VERSION ""

NS_ :

BS_:

BU_:

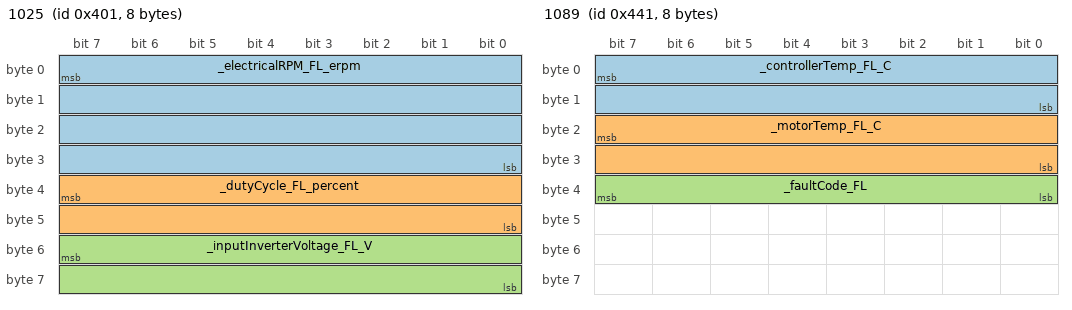
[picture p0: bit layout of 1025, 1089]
BO_ 1025 1025: 8 Vector__XXX
 SG_ _electricalRPM_FL_erpm : 7|32@0+ (1,0) [0|0] "angular_speed:rpm" Vector__XXX
 SG_ _dutyCycle_FL_percent : 39|16@0- (0.1,0) [0|0] "fraction:%" Vector__XXX
 SG_ _inputInverterVoltage_FL_V : 55|16@0- (1,0) [0|0] "voltage:V" Vector__XXX

BO_ 1057 1057: 8 Vector__XXX
 SG_ _motorCurrent_FL_Apk : 7|16@0- (0.1,0) [0|0] "current:A" Vector__XXX
 SG_ _batteryCurrent_FL_A : 23|16@0- (0.1,0) [0|0] "current:A" Vector__XXX

BO_ 1089 1089: 8 Vector__XXX
 SG_ _controllerTemp_FL_C : 7|16@0- (0.1,0) [0|0] "temperature:C" Vector__XXX
 SG_ _motorTemp_FL_C : 23|16@0- (0.1,0) [0|0] "temperature:C" Vector__XXX
 SG_ _faultCode_FL : 39|8@0+ (1,0) [0|0] "unitless:" Vector__XXX

BO_ 1121 1121: 8 Vector__XXX
 SG_ _idPeak_FL_A : 7|32@0- (0.01,0) [0|0] "current:A" Vector__XXX
 SG_ _iqPeak_FL_A : 39|32@0- (0.01,0) [0|0] "current:A" Vector__XXX

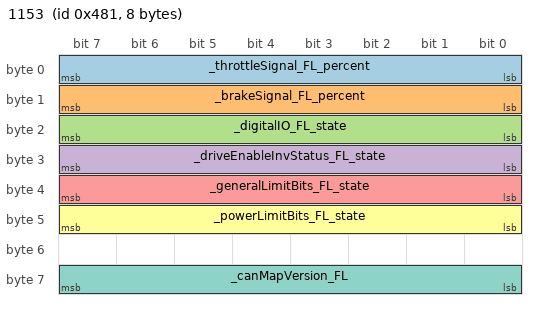
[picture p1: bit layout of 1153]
BO_ 1153 1153: 8 Vector__XXX
 SG_ _throttleSignal_FL_percent : 7|8@0+ (1,0) [0|0] "fraction:%" Vector__XXX
 SG_ _brakeSignal_FL_percent : 15|8@0+ (1,0) [0|0] "fraction:%" Vector__XXX
 SG_ _digitalIO_FL_state : 23|8@0+ (1,0) [0|0] "unitless:" Vector__XXX
 SG_ _driveEnableInvStatus_FL_state : 31|8@0+ (1,0) [0|0] "unitless:" Vector__XXX
 SG_ _generalLimitBits_FL_state : 39|8@0+ (1,0) [0|0] "unitless:" Vector__XXX
 SG_ _powerLimitBits_FL_state : 47|8@0+ (1,0) [0|0] "unitless:" Vector__XXX
 SG_ _canMapVersion_FL : 63|8@0+ (1,0) [0|0] "unitless:" Vector__XXX

BO_ 993 993: 8 Vector__XXX
 SG_ _controlMode_FL : 7|8@0+ (1,0) [0|0] "unitless:" Vector__XXX
